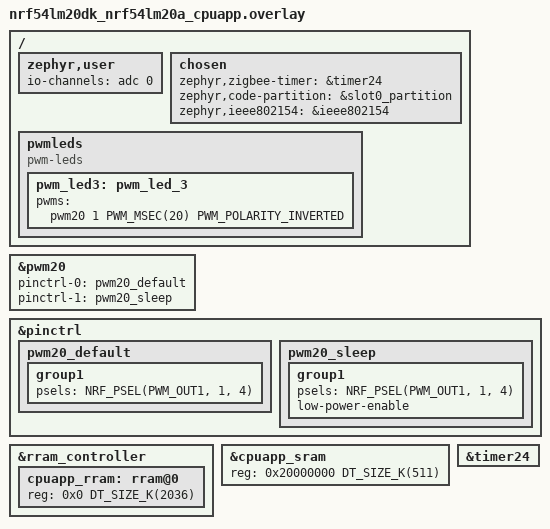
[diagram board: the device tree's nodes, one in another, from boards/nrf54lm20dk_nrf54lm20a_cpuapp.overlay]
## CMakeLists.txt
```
#
# Copyright (c) 2026 Nordic Semiconductor ASA
#
# SPDX-License-Identifier: LicenseRef-Nordic-5-Clause
#

cmake_minimum_required(VERSION 3.20.0)

find_package(Zephyr REQUIRED HINTS $ENV{ZEPHYR_BASE})

project("Matter + Zigbee Light Switch")

include(${ZEPHYR_CONNECTEDHOMEIP_MODULE_DIR}/config/nrfconnect/app/enable-gnu-std.cmake)
include(${ZEPHYR_NRF_MODULE_DIR}/samples/matter/common/cmake/source_common.cmake)
include(${ZEPHYR_NRF_MODULE_DIR}/samples/matter/common/cmake/data_model.cmake)
include(${ZEPHYR_NRF_MODULE_DIR}/samples/matter/common/cmake/zap_helpers.cmake)
ncs_get_zap_parent_dir(ZAP_PARENT_DIR)

target_include_directories(app PRIVATE
	src
	include
	${ZAP_PARENT_DIR}
)

target_compile_options(app PRIVATE -Wno-deprecated-declarations)

target_sources(app PRIVATE
	src/main.cpp
	src/app_task_matter.cpp
	src/app_task_zigbee.c
	src/zboss_mem_globals.c
	src/light_switch.cpp
	src/shell_commands.cpp
	${ZEPHYR_NRF_MODULE_DIR}/samples/matter/common/src/binding/binding_handler.cpp
)

# LTO link: zb_memconfig.o from prebuilts is plain ELF (weak gc_*); strong gc_*
# in zb_mem_config_context.h must not be LTO bytecode or ld warns about symbol size.
if(CONFIG_LTO)
	set_source_files_properties(
		src/zboss_mem_globals.c
		PROPERTIES COMPILE_OPTIONS -fno-lto
	)
endif()

ncs_configure_data_model()
```

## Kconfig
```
#
# Copyright (c) 2024-2026 Nordic Semiconductor ASA
#
# SPDX-License-Identifier: LicenseRef-Nordic-5-Clause
#

if OPENTHREAD

choice OPENTHREAD_NORDIC_LIBRARY_CONFIGURATION
	default OPENTHREAD_NORDIC_LIBRARY_MTD
endchoice

choice OPENTHREAD_DEVICE_TYPE
	default OPENTHREAD_MTD
endchoice

config CHIP_ENABLE_ICD_SUPPORT
	default y

endif # OPENTHREAD

if ZIGBEE_BT_DFU

config BT_DEVICE_NAME
	default "Zigbee_Switch"

endif # ZIGBEE_BT_DFU

config MPSL_THREAD_COOP_PRIO
	default 8

source "$(ZEPHYR_CONNECTEDHOMEIP_MODULE_DIR)/config/nrfconnect/chip-module/Kconfig.features"
source "$(ZEPHYR_CONNECTEDHOMEIP_MODULE_DIR)/config/nrfconnect/chip-module/Kconfig.defaults"
source "$(ZEPHYR_NRF_MODULE_DIR)/samples/matter/common/src/Kconfig"

menu "Zephyr Kernel"
source "Kconfig.zephyr"
endmenu

module = NUS_CMD
module-str = NUS command
source "${ZEPHYR_BASE}/subsys/logging/Kconfig.template.log_config"


config LIGHT_SWITCH_CONFIGURE_TX_POWER
	bool "Configure TX power"
	default y
	help
		Enable this option to configure TX power for the sample.

config LIGHT_SWITCH_TX_POWER
	int "TX power"
	depends on LIGHT_SWITCH_CONFIGURE_TX_POWER
	default 0
	help
		TX power level in dBm.

config LIGHT_SWITCH_ZIGBEE_SLEEPY
	bool "Zigbee Sleepy End Device"
	depends on !ZIGBEE_TOUCHLINK_INITIATOR
	default y
	help
		Configure the Zigbee End Device as a Sleepy End Device
		(receiver off when idle, polling its parent for traffic).

		This option cannot be enabled together with
		CONFIG_ZIGBEE_TOUCHLINK_INITIATOR. Touchlink commissioning requires
		the radio receiver to stay active for inter-PAN traffic, which is
		incompatible with sleepy End Device behavior.
```

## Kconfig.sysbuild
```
#
# Copyright (c) 2024-2026 Nordic Semiconductor
#
# SPDX-License-Identifier: LicenseRef-Nordic-5-Clause
#

config NRF_DEFAULT_IPC_RADIO
	default y

# Enable IEEE802.15.4 serialization to network core for Zigbee
config NETCORE_IPC_RADIO_IEEE802154
	default y if SOC_SERIES_NRF53

#### Bootloader
choice BOOTLOADER
	default BOOTLOADER_MCUBOOT
endchoice

if BOOTLOADER_MCUBOOT

#### DFU multi-image support
config DFU_MULTI_IMAGE_PACKAGE_BUILD
	default y

config DFU_MULTI_IMAGE_PACKAGE_APP
	default y

#### DFU dual core configuration
if SOC_SERIES_NRF53

config PM_EXTERNAL_FLASH_MCUBOOT_SECONDARY
	default y

config MCUBOOT_UPDATEABLE_IMAGES
	default 2

choice MCUBOOT_MODE
	default MCUBOOT_MODE_OVERWRITE_ONLY
endchoice

config SECURE_BOOT_NETCORE
	default y

config NETCORE_APP_UPDATE
	default y

config DFU_MULTI_IMAGE_PACKAGE_NET
	default y

endif # SOC_SERIES_NRF53

endif # BOOTLOADER_MCUBOOT

source "${ZEPHYR_BASE}/share/sysbuild/Kconfig"
```

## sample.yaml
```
sample:
  description: Combined Matter + Zigbee dimmable light switch sample
  name: Matter + Zigbee Light switch
common:
  tags:
    - ci_build
    - smoke
    - sysbuild
    - ci_samples_matter_zigbee
tests:
  sample.matter_zigbee.light_switch:
    sysbuild: true
    build_only: true
    extra_args:
      - SNIPPET=ext_flash
    integration_platforms:
      - nrf54l15dk/nrf54l15/cpuapp
      - nrf54lm20dk/nrf54lm20b/cpuapp
    platform_allow:
      - nrf54l15dk/nrf54l15/cpuapp
      - nrf54lm20dk/nrf54lm20a/cpuapp
      - nrf54lm20dk/nrf54lm20b/cpuapp
  sample.matter_zigbee.light_switch.int_flash:
    sysbuild: true
    build_only: true
    integration_platforms:
      - nrf54lm20dk/nrf54lm20b/cpuapp
    platform_allow:
      - nrf54lm20dk/nrf54lm20a/cpuapp
      - nrf54lm20dk/nrf54lm20b/cpuapp
  sample.matter_zigbee.light_switch.release:
    sysbuild: true
    build_only: true
    extra_args:
      - SNIPPET=ext_flash
      - EXTRA_CONF_FILE=release.conf
    platform_allow:
      - nrf54l15dk/nrf54l15/cpuapp
      - nrf54lm20dk/nrf54lm20a/cpuapp
      - nrf54lm20dk/nrf54lm20b/cpuapp
    tags:
      - no_integration
  sample.matter_zigbee.light_switch.touchlink:
    sysbuild: true
    build_only: true
    extra_args:
      - SNIPPET=ext_flash
      - CONFIG_ZIGBEE_TOUCHLINK_INITIATOR=y
    platform_allow:
      - nrf54l15dk/nrf54l15/cpuapp
      - nrf54lm20dk/nrf54lm20a/cpuapp
      - nrf54lm20dk/nrf54lm20b/cpuapp
    tags:
      - no_integration
  sample.matter_zigbee.light_switch.zigbee_fota:
    sysbuild: true
    build_only: true
    extra_args:
      - SNIPPET=ext_flash
      - EXTRA_CONF_FILE=zigbee_fota.conf
    platform_allow:
      - nrf54l15dk/nrf54l15/cpuapp
      - nrf54lm20dk/nrf54lm20a/cpuapp
      - nrf54lm20dk/nrf54lm20b/cpuapp
    tags:
      - no_integration
  sample.matter_zigbee.light_switch.touchlink.power_consumption_testing:
    sysbuild: true
    build_only: true
    extra_args:
      - SNIPPET=ext_flash
      - CONFIG_ZIGBEE_TOUCHLINK_INITIATOR=y
      - EXTRA_CONF_FILE=release.conf
      - CONFIG_MATTER_ZIGBEE_UI_DISABLE_LEDS=y
    platform_allow:
      - nrf54l15dk/nrf54l15/cpuapp
      - nrf54lm20dk/nrf54lm20a/cpuapp
      - nrf54lm20dk/nrf54lm20b/cpuapp
    tags:
      - no_integration
```

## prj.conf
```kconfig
#
# Copyright (c) 2026 Nordic Semiconductor ASA
#
# SPDX-License-Identifier: LicenseRef-Nordic-5-Clause
#

CONFIG_MATTER_ZIGBEE_ADD_ON=y

CONFIG_NCS_SAMPLES_DEFAULTS=y

CONFIG_UART_INTERRUPT_DRIVEN=y
CONFIG_SERIAL=y
CONFIG_GPIO=y

CONFIG_CONSOLE=y
CONFIG_UART_CONSOLE=y

CONFIG_HEAP_MEM_POOL_SIZE=2048
CONFIG_MAIN_STACK_SIZE=10240
CONFIG_MAIN_THREAD_PRIORITY=7

#######################
# Zigbee Configuration
#######################

CONFIG_ZIGBEE_ADD_ON=y
CONFIG_ZIGBEE_APP_UTILS=y
CONFIG_ZIGBEE_APP_UTILS_LOG_LEVEL_INF=y
CONFIG_ZIGBEE_ROLE_END_DEVICE=y

CONFIG_DK_LIBRARY=y

CONFIG_RAM_POWER_DOWN_LIBRARY=y

CONFIG_ZBOSS_OSIF_LOG_LEVEL_INF=y
CONFIG_MATTER_ZIGBEE_COEXISTENCE_LOG_LEVEL_INF=y

#######################
# Matter Configuration
#######################

CONFIG_CHIP=y
CONFIG_CHIP_PROJECT_CONFIG="include/chip_project_config.h"
CONFIG_CHIP_DEVICE_PRODUCT_NAME="Matter Zigbee Light Switch"

CONFIG_NCS_SAMPLE_MATTER_ZAP_FILE_PATH="${APPLICATION_CONFIG_DIR}/src/default_zap/light_switch.zap"

CONFIG_CHIP_DEVICE_PRODUCT_ID=32772
CONFIG_STD_CPP17=y

CONFIG_CHIP_ENABLE_PAIRING_AUTOSTART=y
CONFIG_CHIP_BLE_EXT_ADVERTISING=y
CONFIG_CHIP_BLE_ADVERTISING_DURATION=60

CONFIG_BT_DEVICE_NAME="MatterZigbeeSw"

CONFIG_THREAD_NAME=y
CONFIG_MPU_STACK_GUARD=y
CONFIG_RESET_ON_FATAL_ERROR=n

# Reduce application size
CONFIG_USE_SEGGER_RTT=n

# Increase system workqueue stack for combined protocols (with Thread)
CONFIG_SYSTEM_WORKQUEUE_STACK_SIZE=6144

# Must be a preemptible priority (0–15), not cooperative (-1). With -1, ZBOSS is
# coop priority -1 and is outranked by MPSL Work (prio -8), so it never runs.
# State 128 = _THREAD_QUEUED (runnable); ZBOSS stays queued and never gets CPU.
CONFIG_ZBOSS_DEFAULT_THREAD_PRIORITY=1
CONFIG_ZBOSS_DEFAULT_THREAD_STACK_SIZE=6144

# Libc malloc arena required for Zigbee + Matter coexistence.
# - 0: no libc heap -> Matter init fails (malloc/calloc used during init).
# - -1: "all remaining RAM" -> on this build the computed heap extends past
#        valid SRAM and faults at first free().
# - Fixed value sized for Matter + Thread + Zigbee (empirical):
#   ~96 KB covers Matter CASE session, Thread buffers, and Zigbee allocations
#   without running the heap off the end of usable SRAM.
CONFIG_COMMON_LIBC_MALLOC_ARENA_SIZE=-1

## PoC Configuration ##
# Keep Matter shell disabled to avoid getopt conflicts
CONFIG_CHIP_LIB_SHELL=n
CONFIG_NCS_SAMPLE_MATTER_TEST_SHELL=n

# Radio dispatcher
CONFIG_NRF_802154_CALLBACKS_DISPATCHER=y
CONFIG_NRF_802154_DRV_REINIT_ENABLED=y

# We need it to disable ZBOSS thread
CONFIG_ZIGBEE_DEBUG_FUNCTIONS=y

CONFIG_CHIP_FACTORY_DATA_BUILD=y

# DFU over Bluetooth LE SMP
CONFIG_CHIP_DFU_OVER_BT_SMP=y
CONFIG_NCS_SAMPLE_MATTER_CUSTOM_BLUETOOTH_ADVERTISING=y
```

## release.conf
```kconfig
#
# Copyright (c) 2026 Nordic Semiconductor ASA
#
# SPDX-License-Identifier: LicenseRef-Nordic-5-Clause
#
# Release configuration for combined Zigbee + Matter + Thread (PoC)
# Strips logging/console/debug and enables size and power optimizations.

#######################
# Release Optimizations
#######################

CONFIG_USE_SEGGER_RTT=n
CONFIG_SHELL=n
CONFIG_OPENTHREAD_SHELL=n
CONFIG_CONSOLE=n
CONFIG_UART_CONSOLE=n
CONFIG_SERIAL=n
CONFIG_UART_INTERRUPT_DRIVEN=n
CONFIG_LOG=n
CONFIG_LOG_MODE_MINIMAL=n
CONFIG_ASSERT_VERBOSE=n
CONFIG_ASSERT_NO_FILE_INFO=y
CONFIG_PRINTK=n
CONFIG_PRINTK_SYNC=n
CONFIG_BOOT_BANNER=n

# Enable LTO to decrease the flash usage
CONFIG_LTO=y
CONFIG_ISR_TABLES_LOCAL_DECLARATION=y

CONFIG_SIZE_OPTIMIZATIONS=y
CONFIG_COMPILER_OPT="-Os"

#######################
# Power Optimizations
#######################

CONFIG_PM_DEVICE=y
CONFIG_PM_DEVICE_RUNTIME=y
```

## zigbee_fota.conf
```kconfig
#
# Copyright (c) 2026 Nordic Semiconductor ASA
#
# SPDX-License-Identifier: LicenseRef-Nordic-5-Clause
#

# Enable Zigbee FOTA library
CONFIG_ZIGBEE_FOTA=y
CONFIG_ZIGBEE_FOTA_HW_VERSION=54
CONFIG_ZIGBEE_FOTA_ENDPOINT=5
CONFIG_MCUBOOT_IMGTOOL_SIGN_VERSION="1.0.0"
CONFIG_ZIGBEE_FOTA_COMMENT="light_switch"

# Ensure an MCUboot-compatible binary is generated.
CONFIG_IMG_MANAGER=y
CONFIG_STREAM_FLASH=y
CONFIG_DFU_TARGET_MCUBOOT=y
CONFIG_IMG_ERASE_PROGRESSIVELY=y
CONFIG_ZIGBEE_FOTA_PROGRESS_EVT=y

# Increase the number of RX buffers for FOTA
CONFIG_NRF_802154_RX_BUFFERS=32
```

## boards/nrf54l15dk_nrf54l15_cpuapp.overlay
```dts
/*
 * Copyright (c) 2026 Nordic Semiconductor ASA
 *
 * SPDX-License-Identifier: LicenseRef-Nordic-5-Clause
 */

#include <nrf54l15dk_cpuapp_partitions.dtsi>

/ {
	chosen {
		ncs,zigbee-timer = &timer20;
		zephyr,code-partition = &slot0_partition;
		zephyr,ieee802154 = &ieee802154;
	};

	pwmleds {
		compatible = "pwm-leds";

		pwm_led3: pwm_led_3 {
			pwms = <&pwm20 1 PWM_MSEC(20) PWM_POLARITY_NORMAL>;
		};
	};
};

&cpuapp_rram {
	reg = <0x0 DT_SIZE_K(1524)>;
};

&cpuapp_sram {
	reg = <0x20000000 DT_SIZE_K(256)>;
	ranges = <0x0 0x20000000 0x40000>;
};

&pwm20 {
	status = "okay";
	pinctrl-0 = <&pwm_default>;
	pinctrl-1 = <&pwm_sleep>;
	pinctrl-names = "default", "sleep";
};

&pinctrl {
	pwm_default: pwm_default {
		group1 {
			psels = <NRF_PSEL(PWM_OUT1, 1, 10)>;
		};
	};

	pwm_sleep: pwm_sleep {
		group1 {
			psels = <NRF_PSEL(PWM_OUT1, 1, 10)>;
			low-power-enable;
		};
	};
};

&timer20 {
	status = "okay";
};
```

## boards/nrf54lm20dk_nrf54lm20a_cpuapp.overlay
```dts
/*
 * Copyright (c) 2026 Nordic Semiconductor ASA
 *
 * SPDX-License-Identifier: LicenseRef-Nordic-5-Clause
 */

#include <nrf54lm20_cpuapp_partitions.dtsi>
#include <nrf54lm20dk_cpuapp_partitions.dtsi>

/ {
	zephyr,user {
		io-channels = <&adc 0>;
	};

	chosen {
		zephyr,zigbee-timer = &timer24;
		zephyr,code-partition = &slot0_partition;
		zephyr,ieee802154 = &ieee802154;
	};

	pwmleds {
		compatible = "pwm-leds";
		pwm_led3: pwm_led_3 {
			pwms = <&pwm20 1 PWM_MSEC(20) PWM_POLARITY_INVERTED>;
		};
	};
};

&pwm20 {
	status = "okay";
	pinctrl-0 = <&pwm20_default>;
	pinctrl-1 = <&pwm20_sleep>;
	pinctrl-names = "default", "sleep";
};

&pinctrl {
	pwm20_default: pwm20_default {
		group1 {
			psels = <NRF_PSEL(PWM_OUT1, 1, 4)>;
		};
	};

	pwm20_sleep: pwm20_sleep {
		group1 {
			psels = <NRF_PSEL(PWM_OUT1, 1, 4)>;
			low-power-enable;
		};
	};
};

/* Restore full RRAM and SRAM (cpuapp_sram is 511K per SoC DTSI). */
&rram_controller {
	cpuapp_rram: rram@0 {
		reg = <0x0 DT_SIZE_K(2036)>;
		ranges = <0x0 0x0 DT_SIZE_K(2036)>;
	};
};

&cpuapp_sram {
	reg = <0x20000000 DT_SIZE_K(511)>;
};

&timer24 {
	status = "okay";
};
```

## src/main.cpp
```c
/*
 * Copyright (c) 2026 Nordic Semiconductor ASA
 *
 * SPDX-License-Identifier: LicenseRef-Nordic-5-Clause
 */

/** @file
 *
 * @brief Matter + Zigbee light switch entry point.
 */

#include "app_task_matter.h"
#include "app_task_zigbee.h"

#include <matter_zigbee_coexistence.h>
#include <matter_zigbee_ui.h>

#include <zephyr/logging/log.h>

LOG_MODULE_REGISTER(app, CONFIG_CHIP_APP_LOG_LEVEL);

namespace
{

void matter_start_cb(void)
{
	AppTask::Instance().StartApp();
}

bool app_ui_button_handler(uint32_t button_state, uint32_t has_changed, active_protocol_t active_protocol)
{
	if (active_protocol == PROTOCOL_ZIGBEE) {
		zb_button_handler(button_state, has_changed);
	}

	if (active_protocol == PROTOCOL_MATTER) {
		AppTask::ButtonEventHandler(button_state, has_changed);
	}

	return false;
}

const struct matter_zigbee_ui_callbacks ui_callbacks = {
	.on_button = app_ui_button_handler,
};

const struct matter_zigbee_coexistence_callbacks coexistence_cb = {
	matter_start_cb,
	ZigbeeStart,
	matter_zigbee_ui_register,
};

} /* namespace */

int main(void)
{
	matter_zigbee_ui_set_callbacks(&ui_callbacks);
	return matter_zigbee_coexistence_run(&coexistence_cb);
}
```

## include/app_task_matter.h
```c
/*
 * Copyright (c) 2026 Nordic Semiconductor ASA
 *
 * SPDX-License-Identifier: LicenseRef-Nordic-5-Clause
 */

#pragma once

#include "board/board.h"

#include <platform/CHIPDeviceLayer.h>

struct k_timer;
struct Identify;

class AppTask {
public:
	static AppTask &Instance()
	{
		static AppTask sAppTask;
		return sAppTask;
	};

	CHIP_ERROR StartApp();

	void UpdateClusterState();

	static void ButtonEventHandler(Nrf::ButtonState state, Nrf::ButtonMask hasChanged);

private:
	enum Timer : uint8_t { DimmerTrigger, Dimmer };

	CHIP_ERROR Init();

	static void DimmerTriggerEventHandler();
	static void TimerEventHandler(const Timer &event);

	static void StartTimer(Timer, uint32_t);
	static void CancelTimer(Timer);
	static void UserTimerTimeoutCallback(k_timer *timer);
};
```

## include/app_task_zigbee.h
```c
/*
 * Copyright (c) 2026 Nordic Semiconductor ASA
 *
 * SPDX-License-Identifier: LicenseRef-Nordic-5-Clause
 */

#ifndef APP_TASK_ZIGBEE_H
#define APP_TASK_ZIGBEE_H 1

#include <stdint.h>

#ifdef __cplusplus
extern "C" {
#endif

int ZigbeeStart(void);

#ifdef CONFIG_MATTER_ZIGBEE_COEXISTENCE
/**
 * @brief Sample-specific button handler for Zigbee in combined builds.
 *
 * Invoked from the common UI module when a button event is received.
 * Processes button events when Zigbee protocol is active and returns early
 * if Matter is active.
 *
 * @param button_state  Bitmask containing buttons state.
 * @param has_changed   Bitmask containing buttons that changed state.
 */
void zb_button_handler(uint32_t button_state, uint32_t has_changed);
#endif /* CONFIG_MATTER_ZIGBEE_COEXISTENCE */

#ifdef __cplusplus
}
#endif

#endif /* APP_TASK_ZIGBEE_H */
```

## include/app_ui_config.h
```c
/*
 * Copyright (c) 2026 Nordic Semiconductor ASA
 *
 * SPDX-License-Identifier: LicenseRef-Nordic-5-Clause
 */

#ifndef APP_UI_CONFIG_H_
#define APP_UI_CONFIG_H_

/** @file
 * @brief Light switch sample UI configuration (buttons and LEDs).
 *
 * Common Matter + Zigbee UI buttons and LEDs are defined in
 * @ref matter_zigbee_ui_config.h. This file adds sample-specific mappings
 * shared by the Matter and Zigbee application tasks.
 */

#include <matter_zigbee_ui_config.h>

#include <zephyr/kernel.h>

/** Button 3: toggle/dim bound lights (Zigbee) or dimmer trigger (Matter). */
#define APP_UI_BUTTON_LIGHT_TOGGLE DK_BTN3_MSK

#if defined(CONFIG_ZIGBEE_TOUCHLINK_INITIATOR)
/** Button 2 short press: Touchlink initiator (Zigbee). */
#define APP_UI_BUTTON_ZIGBEE_TOUCHLINK DK_BTN2_MSK
#endif

#if defined(CONFIG_CHIP_ICD_UAT_SUPPORT)
/** Button 2: ICD User Active Mode trigger (Matter). */
#define APP_UI_BUTTON_MATTER_ICD_UAT DK_BTN2_MSK
#endif

/** LED solid on when a controllable bulb has been found (Zigbee). */
#define APP_UI_LED_ZIGBEE_BULB_FOUND DK_LED4

/** Hold time before continuous dim-up steps start (Zigbee). */
#define APP_UI_BUTTON_ZIGBEE_LONG_PRESS_TIMEOUT K_MSEC(500)

#endif /* APP_UI_CONFIG_H_ */
```

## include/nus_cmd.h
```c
/*
 * Copyright (c) 2024 Nordic Semiconductor ASA
 *
 * SPDX-License-Identifier: LicenseRef-Nordic-5-Clause
 */

/**
 * @file nus_cmd.h
 *
 * @brief APIs for NUS Command Service.
 */

#ifndef __NUS_CMD_H__
#define __NUS_CMD_H__

/** @brief Type indicates function called when Bluetooth LE connection
 *         is established.
 *
 * @param[in] item pointer to work item.
 */
typedef void (*nus_connection_cb_t)(struct k_work *item);

/** @brief Type indicates function called when Bluetooth LE connection is ended.
 *
 * @param[in] item pointer to work item.
 */
typedef void (*nus_disconnection_cb_t)(struct k_work *item);

/** @brief NUS command entry.
 */
struct nus_entry {
	const char *cmd; /**< Command string. */
	struct k_work work; /**< Command work item. */
};

/**@brief Macro to initialise (bind) command string to work handler.
 */
#define NUS_COMMAND(_cmd, _handler)                                                                                    \
	{                                                                                                              \
		.work = Z_WORK_INITIALIZER(_handler), .cmd = _cmd,                                                     \
	}

/**@brief Function to initialise NUS Command service.
 *
 * @param[in] on_connect Callback that will be called when central connects to
 *			 the NUS service.
 * @param[in] on_disconnect Callback that will be called when BLE central
 *			    disconnects from the NUS service.
 * @param[in] command_set   A pointer to an array with NUS commands.
 */
void nus_cmd_init(nus_connection_cb_t on_connect, nus_disconnection_cb_t on_disconnect, struct nus_entry *command_set);

#endif
```

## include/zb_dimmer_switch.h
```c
/*
 * Copyright (c) 2024 Nordic Semiconductor ASA
 *
 * SPDX-License-Identifier: LicenseRef-Nordic-5-Clause
 */

#ifndef ZB_DIMMER_SWITCH_H
#define ZB_DIMMER_SWITCH_H 1

/**
 *  @defgroup ZB_DEFINE_DEVICE_DIMMER_SWITCH Dimmer Switch
 *  @{
 *  @details
 *      - @ref ZB_ZCL_BASIC \n
 *      - @ref ZB_ZCL_IDENTIFY \n
 *      - @ref ZB_ZCL_SCENES \n
 *      - @ref ZB_ZCL_GROUPS \n
 *      - @ref ZB_ZCL_ON_OFF \n
 *      - @ref ZB_ZCL_LEVEL_CONTROL
 */

/** Dimmer Switch Device ID */
#define ZB_DIMMER_SWITCH_DEVICE_ID 0x0104

/** Dimmer Switch device version */
#define ZB_DEVICE_VER_DIMMER_SWITCH 0

/** @cond internals_doc */

/** Dimmer Switch IN (server) clusters number */
#define ZB_DIMMER_SWITCH_IN_CLUSTER_NUM 2

/** Dimmer Switch OUT (client) clusters number */
#define ZB_DIMMER_SWITCH_OUT_CLUSTER_NUM 5

/** Dimmer switch total (IN+OUT) cluster number */
#define ZB_DIMMER_SWITCH_CLUSTER_NUM (ZB_DIMMER_SWITCH_IN_CLUSTER_NUM + ZB_DIMMER_SWITCH_OUT_CLUSTER_NUM)

/** Number of attribute for reporting on Dimmer Switch device */
#define ZB_DIMMER_SWITCH_REPORT_ATTR_COUNT 0

/** @endcond */ /* internals_doc */

/**
 * @brief Declare cluster list for Dimmer Switch device
 * @param cluster_list_name - cluster list variable name
 * @param basic_server_attr_list - attribute list for Basic cluster (server role)
 * @param identify_client_attr_list - attribute list for Identify cluster (client role)
 * @param identify_server_attr_list - attribute list for Identify cluster (server role)
 * @param scenes_client_attr_list - attribute list for Scenes cluster (client role)
 * @param groups_client_attr_list - attribute list for Groups cluster (client role)
 * @param on_off_client_attr_list - attribute list for On/Off cluster (client role)
 * @param level_control_client_attr_list - attribute list for Level Control cluster (client role)
 */
#define ZB_DECLARE_DIMMER_SWITCH_CLUSTER_LIST(cluster_list_name, basic_server_attr_list, identify_client_attr_list,    \
					      identify_server_attr_list, scenes_client_attr_list,                      \
					      groups_client_attr_list, on_off_client_attr_list,                        \
					      level_control_client_attr_list)                                          \
	zb_zcl_cluster_desc_t cluster_list_name[] = {                                                                  \
		ZB_ZCL_CLUSTER_DESC(ZB_ZCL_CLUSTER_ID_BASIC, ZB_ZCL_ARRAY_SIZE(basic_server_attr_list, zb_zcl_attr_t), \
				    (basic_server_attr_list), ZB_ZCL_CLUSTER_SERVER_ROLE, ZB_ZCL_MANUF_CODE_INVALID),  \
		ZB_ZCL_CLUSTER_DESC(                                                                                   \
			ZB_ZCL_CLUSTER_ID_IDENTIFY, ZB_ZCL_ARRAY_SIZE(identify_server_attr_list, zb_zcl_attr_t),       \
			(identify_server_attr_list), ZB_ZCL_CLUSTER_SERVER_ROLE, ZB_ZCL_MANUF_CODE_INVALID),           \
		ZB_ZCL_CLUSTER_DESC(                                                                                   \
			ZB_ZCL_CLUSTER_ID_IDENTIFY, ZB_ZCL_ARRAY_SIZE(identify_client_attr_list, zb_zcl_attr_t),       \
			(identify_client_attr_list), ZB_ZCL_CLUSTER_CLIENT_ROLE, ZB_ZCL_MANUF_CODE_INVALID),           \
		ZB_ZCL_CLUSTER_DESC(ZB_ZCL_CLUSTER_ID_SCENES,                                                          \
				    ZB_ZCL_ARRAY_SIZE(scenes_client_attr_list, zb_zcl_attr_t),                         \
				    (scenes_client_attr_list), ZB_ZCL_CLUSTER_CLIENT_ROLE, ZB_ZCL_MANUF_CODE_INVALID), \
		ZB_ZCL_CLUSTER_DESC(ZB_ZCL_CLUSTER_ID_GROUPS,                                                          \
				    ZB_ZCL_ARRAY_SIZE(groups_client_attr_list, zb_zcl_attr_t),                         \
				    (groups_client_attr_list), ZB_ZCL_CLUSTER_CLIENT_ROLE, ZB_ZCL_MANUF_CODE_INVALID), \
		ZB_ZCL_CLUSTER_DESC(ZB_ZCL_CLUSTER_ID_ON_OFF,                                                          \
				    ZB_ZCL_ARRAY_SIZE(on_off_client_attr_list, zb_zcl_attr_t),                         \
				    (on_off_client_attr_list), ZB_ZCL_CLUSTER_CLIENT_ROLE, ZB_ZCL_MANUF_CODE_INVALID), \
		ZB_ZCL_CLUSTER_DESC(ZB_ZCL_CLUSTER_ID_LEVEL_CONTROL,                                                   \
				    ZB_ZCL_ARRAY_SIZE(level_control_client_attr_list, zb_zcl_attr_t),                  \
				    (level_control_client_attr_list), ZB_ZCL_CLUSTER_CLIENT_ROLE,                      \
				    ZB_ZCL_MANUF_CODE_INVALID)                                                         \
	}

/** @cond internals_doc */
/**
 * @brief Declare simple descriptor for Dimmer switch device
 * @param ep_name - endpoint variable name
 * @param ep_id - endpoint ID
 * @param in_clust_num - number of supported input clusters
 * @param out_clust_num - number of supported output clusters
 */
#define ZB_ZCL_DECLARE_DIMMER_SWITCH_SIMPLE_DESC(ep_name, ep_id, in_clust_num, out_clust_num)                          \
	ZB_DECLARE_SIMPLE_DESC(in_clust_num, out_clust_num);                                                           \
	ZB_AF_SIMPLE_DESC_TYPE(in_clust_num, out_clust_num)                                                            \
	simple_desc_##ep_name = { ep_id,                                                                               \
				  ZB_AF_HA_PROFILE_ID,                                                                 \
				  ZB_DIMMER_SWITCH_DEVICE_ID,                                                          \
				  ZB_DEVICE_VER_DIMMER_SWITCH,                                                         \
				  0,                                                                                   \
				  in_clust_num,                                                                        \
				  out_clust_num,                                                                       \
				  {                                                                                    \
					  ZB_ZCL_CLUSTER_ID_BASIC,                                                     \
					  ZB_ZCL_CLUSTER_ID_IDENTIFY,                                                  \
					  ZB_ZCL_CLUSTER_ID_IDENTIFY,                                                  \
					  ZB_ZCL_CLUSTER_ID_SCENES,                                                    \
					  ZB_ZCL_CLUSTER_ID_GROUPS,                                                    \
					  ZB_ZCL_CLUSTER_ID_ON_OFF,                                                    \
					  ZB_ZCL_CLUSTER_ID_LEVEL_CONTROL,                                             \
				  } }

/** @endcond */ /* internals_doc */

/**
 * @brief Declare endpoint for Dimmer Switch device
 * @param ep_name - endpoint variable name
 * @param ep_id - endpoint ID
 * @param cluster_list - endpoint cluster list
 */
#define ZB_DECLARE_DIMMER_SWITCH_EP(ep_name, ep_id, cluster_list)                                                      \
	ZB_ZCL_DECLARE_DIMMER_SWITCH_SIMPLE_DESC(ep_name, ep_id, ZB_DIMMER_SWITCH_IN_CLUSTER_NUM,                      \
						 ZB_DIMMER_SWITCH_OUT_CLUSTER_NUM);                                    \
                                                                                                                       \
	ZB_AF_DECLARE_ENDPOINT_DESC(ep_name, ep_id, ZB_AF_HA_PROFILE_ID, 0, NULL,                                      \
				    ZB_ZCL_ARRAY_SIZE(cluster_list, zb_zcl_cluster_desc_t), cluster_list,              \
				    (zb_af_simple_desc_1_1_t *)&simple_desc_##ep_name, 0, NULL, /* No reporting ctx */ \
				    0, NULL) /* No CVC ctx */

/** @} */

#endif /* ZB_DIMMER_SWITCH_H */
```

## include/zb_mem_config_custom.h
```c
/*
 * Copyright (c) 2024 Nordic Semiconductor ASA
 *
 * SPDX-License-Identifier: LicenseRef-Nordic-5-Clause
 */

#ifndef ZB_MEM_CONFIG_CUSTOM_H
#define ZB_MEM_CONFIG_CUSTOM_H 1

#define ZB_CONFIG_ROLE_ZED
#define ZB_CONFIG_OVERALL_NETWORK_SIZE 16

/**
 * Light routing and application traffic from/to that device.
 */
#define ZB_CONFIG_LIGHT_TRAFFIC

/**
 * Simple user's application at that device: not too many relations
 * to other devices.
 */
#define ZB_CONFIG_APPLICATION_SIMPLE

/**
 * The below section is for advanced users.
 * Before modifying any values, please make sure you fully understand the
 * impact, for example by reading zb_mem_config_common.h
 */
#include "zb_mem_config_common.h"

/**
 * Now if you REALLY know what you do, you can study zb_mem_config_common.h
 * and redefine some configuration parameters, like:
 */
#if defined(CONFIG_LIGHT_SWITCH_CONFIGURE_TX_POWER) && defined(CONFIG_ZIGBEE_CHANNEL_SELECTION_MODE_MULTI)
#undef ZB_CONFIG_SCHEDULER_Q_SIZE
#define ZB_CONFIG_SCHEDULER_Q_SIZE 28
#undef ZB_CONFIG_IOBUF_POOL_SIZE
#define ZB_CONFIG_IOBUF_POOL_SIZE 42
#else
#undef ZB_CONFIG_SCHEDULER_Q_SIZE
#define ZB_CONFIG_SCHEDULER_Q_SIZE 24
#endif /* CONFIG_LIGHT_SWITCH_CONFIGURE_TX_POWER && CONFIG_ZIGBEE_CHANNEL_SELECTION_MODE_MULTI */

/**
 * Increase OTA transfer time by extending the APS duplicate rejection table.
 * This value must be less than the amount of possible APS counter values (256).
 */
#undef ZB_CONFIG_APS_DUPS_TABLE_SIZE
#define ZB_CONFIG_APS_DUPS_TABLE_SIZE 64

/* Memory context definitions. */
#include "zb_mem_config_context.h"

#endif /* ZB_MEM_CONFIG_CUSTOM_H */
```

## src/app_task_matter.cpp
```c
/*
 * Copyright (c) 2026 Nordic Semiconductor ASA
 *
 * SPDX-License-Identifier: LicenseRef-Nordic-5-Clause
 */

#include "app_task_matter.h"

#include "light_switch.h"

#include "app/matter_init.h"
#include "app/task_executor.h"
#include "board/board.h"
#include "clusters/identify.h"

#include <setup_payload/OnboardingCodesUtil.h>

#include <matter_zigbee_coexistence.h>

#if defined(CONFIG_MATTER_ZIGBEE_SMP_DFU)
#include <matter_zigbee_smp_dfu.h>
#endif

#include <zephyr/logging/log.h>

LOG_MODULE_DECLARE(app, CONFIG_CHIP_APP_LOG_LEVEL);

using namespace ::chip;
using namespace ::chip::app;
using namespace ::chip::DeviceLayer;

namespace
{
constexpr uint32_t kDimmerTriggeredTimeout = 500;
constexpr uint32_t kDimmerInterval = 300;
constexpr EndpointId kLightSwitchEndpointId = 1;
constexpr EndpointId kLightEndpointId = 1;

k_timer sDimmerPressKeyTimer;
k_timer sDimmerTimer;

Nrf::Matter::IdentifyCluster sIdentifyCluster(kLightEndpointId);

bool sWasDimmerTriggered = false;

#define APPLICATION_BUTTON_MASK DK_BTN3_MSK

#ifdef CONFIG_CHIP_ICD_UAT_SUPPORT
#define UAT_BUTTON_MASK DK_BTN2_MSK
#endif
} /* namespace */

void AppTask::DimmerTriggerEventHandler()
{
	if (!sWasDimmerTriggered) {
		LightSwitch::GetInstance().InitiateActionSwitch(LightSwitch::Action::Toggle);
	}

	Instance().CancelTimer(Timer::Dimmer);
	Instance().CancelTimer(Timer::DimmerTrigger);
	sWasDimmerTriggered = false;
}

void AppTask::TimerEventHandler(const Timer &timerType)
{
	switch (timerType) {
	case Timer::DimmerTrigger:
		LOG_INF("Dimming started...");
		sWasDimmerTriggered = true;
		LightSwitch::GetInstance().InitiateActionSwitch(LightSwitch::Action::On);
		Instance().StartTimer(Timer::Dimmer, kDimmerInterval);
		Instance().CancelTimer(Timer::DimmerTrigger);
		break;
	case Timer::Dimmer:
		LightSwitch::GetInstance().DimmerChangeBrightness();
		break;
	default:
		break;
	}
}

void AppTask::ButtonEventHandler(Nrf::ButtonState state, Nrf::ButtonMask hasChanged)
{
	if ((APPLICATION_BUTTON_MASK & state & hasChanged)) {
		LOG_INF("Button has been pressed, keep in this state for at least 500 ms to change light sensitivity of bound lighting devices.");
		Instance().StartTimer(Timer::DimmerTrigger, kDimmerTriggeredTimeout);
	} else if ((APPLICATION_BUTTON_MASK & hasChanged)) {
		Nrf::PostTask([] { DimmerTriggerEventHandler(); });
#ifdef CONFIG_CHIP_ICD_UAT_SUPPORT
	} else if ((UAT_BUTTON_MASK & state & hasChanged)) {
		LOG_INF("ICD UserActiveMode has been triggered.");
		Server::GetInstance().GetICDManager().OnNetworkActivity();
#endif
	}
}

void AppTask::StartTimer(Timer timer, uint32_t timeoutMs)
{
	switch (timer) {
	case Timer::DimmerTrigger:
		k_timer_start(&sDimmerPressKeyTimer, K_MSEC(timeoutMs), K_NO_WAIT);
		break;
	case Timer::Dimmer:
		k_timer_start(&sDimmerTimer, K_MSEC(timeoutMs), K_MSEC(timeoutMs));
		break;
	default:
		break;
	}
}

void AppTask::CancelTimer(Timer timer)
{
	switch (timer) {
	case Timer::DimmerTrigger:
		k_timer_stop(&sDimmerPressKeyTimer);
		break;
	case Timer::Dimmer:
		k_timer_stop(&sDimmerTimer);
		break;
	default:
		break;
	}
}

void AppTask::UserTimerTimeoutCallback(k_timer *timer)
{
	if (!timer) {
		return;
	}
	Timer timerType;

	if (timer == &sDimmerPressKeyTimer) {
		timerType = Timer::DimmerTrigger;
	} else if (timer == &sDimmerTimer) {
		timerType = Timer::Dimmer;
	} else {
		return;
	}

	Nrf::PostTask([timerType]() { TimerEventHandler(timerType); });
}

CHIP_ERROR AppTask::Init()
{
	/* Initialize Matter stack */
	Nrf::Matter::InitData initData{};
	initData.mPostServerInitClbk = [] {
		LightSwitch::GetInstance().Init(kLightSwitchEndpointId);
		return CHIP_NO_ERROR;
	};
	initData.mPreServerInitClbk = []() -> CHIP_ERROR {
		matter_zigbee_coexistence_pre_server_init();
		return CHIP_NO_ERROR;
	};
	ReturnErrorOnFailure(Nrf::Matter::PrepareServer(initData));

	/* Initialize application timers */
	k_timer_init(&sDimmerPressKeyTimer, AppTask::UserTimerTimeoutCallback, nullptr);
	k_timer_init(&sDimmerTimer, AppTask::UserTimerTimeoutCallback, nullptr);

// 	if (!Nrf::GetBoard().Init(ButtonEventHandler)) {
// 		LOG_ERR("User interface initialization failed.");
// 		return CHIP_ERROR_INCORRECT_STATE;
// 	}

// #if defined(CONFIG_MATTER_ZIGBEE_SMP_DFU)
// 	matter_zigbee_smp_dfu_init();
// #endif

// 	/* Register Matter event handler that controls the connectivity status LED based on the captured Matter network
// 	 * state. */
// 	ReturnErrorOnFailure(Nrf::Matter::RegisterEventHandler(Nrf::Board::DefaultMatterEventHandler, 0));

	ReturnErrorOnFailure(sIdentifyCluster.Init());

	ReturnErrorOnFailure(Nrf::Matter::StartServer());

	matter_zigbee_coexistence_on_server_started();

	return CHIP_NO_ERROR;
}

CHIP_ERROR AppTask::StartApp()
{
	ReturnErrorOnFailure(Init());

	while (true) {
		Nrf::DispatchNextTask();
	}

	return CHIP_NO_ERROR;
}
```
